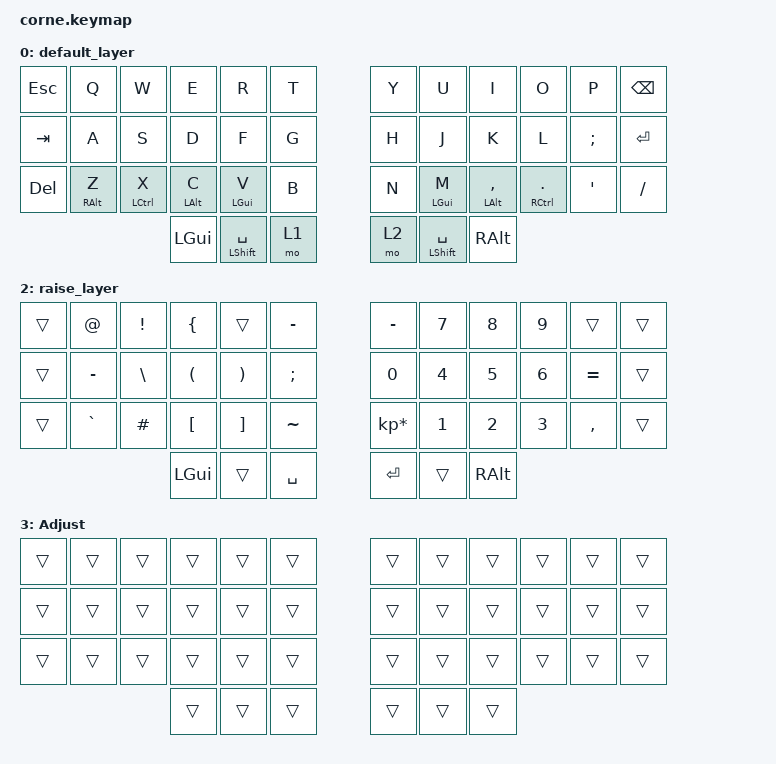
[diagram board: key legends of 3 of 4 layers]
/*
 * Copyright (c) 2020 The ZMK Contributors
 *
 * SPDX-License-Identifier: MIT
 */

#include <behaviors.dtsi>
#include <dt-bindings/zmk/keys.h>

// &ht {
//     flavor = "hold-preferred";
//     tapping_term_ms = <200>;
// };
// &mt {
//     flavor = "tap-preferred";
//     tapping_term_ms = <200>;
// };
//     conditional_layers {
//         compatible = "zmk,conditional-layers";
//         tri_layer {
//             if-layers = <1 2>;
//             then-layer = <3>;
//         };
//     };
// behaviors{
//  lh_pht: left_positional_hold_tap {
//             compatible = "zmk,behavior-hold-tap";
//             #binding-cells = <2>;
//             flavor = "tap-unless-interrupted";
//             tapping-term-ms = <100>;                        // <---[[produces tap if held longer than tapping-term-ms]]
//             quick-tap-ms = <200>;
//             bindings = <&kp>, <&kp>;
//             hold-trigger-key-positions = <5 6 7 8 9 10>;    // <---[[right-hand keys]]
//         };
// };

&mt { flavor = "tap-unless-interrupted"; };

/ {
    keymap {
        compatible = "zmk,keymap";

        default_layer {
            // -----------------------------------------------------------------------------------------
            // |  TAB |  Q  |  W  |  E  |  R  |  T  |   |  Y  |  U   |  I  |  O  |  P  | BKSP |
            // | CTRL |  A  |  S  |  D  |  F  |  G  |   |  H  |  J   |  K  |  L  |  ;  |  '   |
            // | SHFT |  Z  |  X  |  C  |  V  |  B  |   |  N  |  M   |  ,  |  .  |  /  | ESC  |
            //                    | GUI | LWR | SPC |   | ENT | RSE  | ALT |

            bindings = <
&kp ESC  &kp Q       &kp W        &kp E       &kp R             &kp T    &kp Y  &kp U             &kp I           &kp O          &kp P     &kp BSPC
&kp TAB  &kp A       &kp S        &kp D       &kp F             &kp G    &kp H  &kp J             &kp K           &kp L          &kp SEMI  &kp RET
&kp DEL  &mt RALT Z  &mt LCTRL X  &mt LALT C  &mt LGUI V        &kp B    &kp N  &mt LGUI M        &mt LALT COMMA  &mt RCTRL DOT  &kp SQT   &kp FSLH
                                  &kp LGUI    &mt LSHIFT SPACE  &mo 1    &mo 2  &mt LSHIFT SPACE  &kp RALT
            >;
        };

        lower_layer {
            // -----------------------------------------------------------------------------------------
            // |  TAB |  1  |  2  |  3  |  4  |  5  |   |  6  |  7  |  8  |  9  |  0  | BKSP |
            // | BTCLR| BT1 | BT2 | BT3 | BT4 | BT5 |   | LFT | DWN |  UP | RGT |     |      |
            // | SHFT |     |     |     |     |     |   |     |     |     |     |     |      |
            //                    | GUI |     | SPC |   | ENT |     | ALT |

            bindings = <
&kp ESC  &kp F1     &kp F2         &kp F3       &kp F4      &kp F5     &kp F6    &kp F7    &kp F8     &kp F9     &kp F10  &kp BSPC
&kp TAB  &kp MINUS  &kp BACKSLASH  &kp EQUAL 1  &kp SEMI 2  &trans     &kp LEFT  &kp DOWN  &kp UP     &kp RIGHT  &trans   &trans
&trans   &trans     &trans         &trans       &kp F11     &kp F12    &kp HOME  &kp END   &kp PG_UP  &kp PG_DN  &trans   &trans
                                   &trans       &trans      &trans     &trans    &trans
            >;
        };

        raise_layer {
            // -----------------------------------------------------------------------------------------
            // |  TAB |  !  |  @  |  #  |  $  |  %  |   |  ^  |  &  |  *  |  (  |  )  | BKSP |
            // | CTRL |     |     |     |     |     |   |  -  |  =  |  [  |  ]  |  \  |  `   |
            // | SHFT |     |     |     |     |     |   |  _  |  +  |  {  |  }  | "|" |  ~   |
            //                    | GUI |     | SPC |   | ENT |     | ALT |

            bindings = <
&trans  &kp AT     &kp EXCL  &kp LBRC  &trans    &kp MINUS    &kp MINUS        &kp N7        &kp N8        &kp N9        &trans     &trans
&trans  &kp MINUS  &kp BSLH  &kp LPAR  &kp RPAR  &kp SEMI     &kp N0           &kp NUMBER_4  &kp N5        &kp NUMBER_6  &kp EQUAL  &trans
&trans  &kp GRAVE  &kp HASH  &kp LBKT  &kp RBKT  &kp TILDE    &kp KP_MULTIPLY  &kp NUMBER_1  &kp NUMBER_2  &kp NUMBER_3  &kp COMMA  &trans
                             &kp LGUI  &trans    &kp SPACE    &kp RET          &trans        &kp RALT
            >;
        };

        ADJUST_LAYER {
            bindings = <
&trans  &trans  &trans  &trans  &trans  &trans    &trans  &trans  &trans  &trans  &trans  &trans
&trans  &trans  &trans  &trans  &trans  &trans    &trans  &trans  &trans  &trans  &trans  &trans
&trans  &trans  &trans  &trans  &trans  &trans    &trans  &trans  &trans  &trans  &trans  &trans
                        &trans  &trans  &trans    &trans  &trans  &trans
            >;

            label = "Adjust";
        };
    };

    conditional_layers {
        compatible = "zmk,conditional-layers";

        adjust {
            if-layers = <1 2>;
            then-layer = <3>;
        };
    };
};
